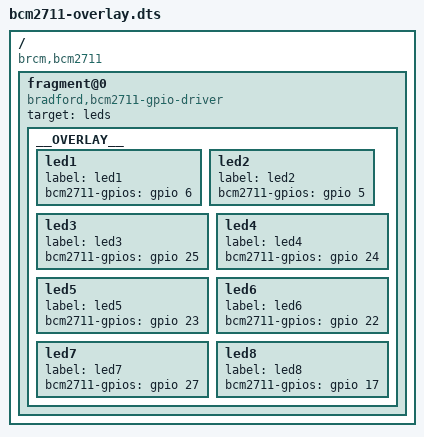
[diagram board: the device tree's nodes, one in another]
// #include <dt-bindings/gpio/gpio.h>
// #include <dt-bindings/pinctrl/bcm2835.h>

/dts-v1/;
/plugin/;

/ {
  compatible = "brcm,bcm2711";

  fragment@0 {
    target = <&leds>;
    compatible = "bradford,bcm2711-gpio-driver";
    __OVERLAY__ {
      led1 {
        label = "led1";
        bcm2711-gpios = <&gpio 6 0>;
      };
      led2 {
        label = "led2";
        bcm2711-gpios = <&gpio 5 0>;
      };
      led3 {
        label = "led3";
        bcm2711-gpios = <&gpio 25 0>;
      };
      led4 {
        label = "led4";
        bcm2711-gpios = <&gpio 24 0>;
      };
      led5 {
        label = "led5";
        bcm2711-gpios = <&gpio 23 0>;
      };
      led6 {
        label = "led6";
        bcm2711-gpios = <&gpio 22 0>;
      };
      led7 {
        label = "led7";
        bcm2711-gpios = <&gpio 27 0>;
      };
      led8 {
        label = "led8";
        bcm2711-gpios = <&gpio 17 0>;
      };
    };
  };

  __symbols__ {
    leds = "/leds";
  };
};
